# 3066H register map
File version: 1.0
Registers are 32-bit, access per field, reset 0x0 unless marked. A register's access mark holds for its fields unless they carry their own. Offsets are from the block's base; [hi:lo] are bit positions; {n}, {i} and the like mark numbered series.

## SYSCTRL1 — SYSCTRL1 peripheral interface
Base 0x10100000
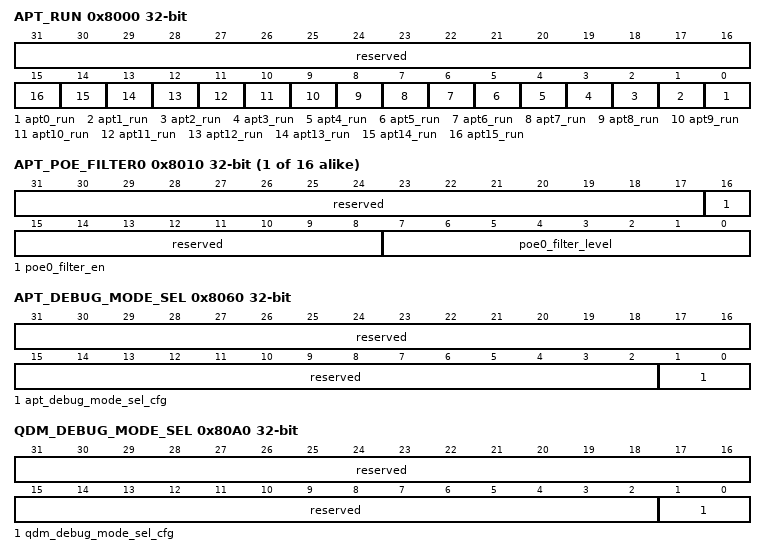
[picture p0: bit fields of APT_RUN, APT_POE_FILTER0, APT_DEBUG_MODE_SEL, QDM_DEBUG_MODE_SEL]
0x8000 APT_RUN — APT_RUN为APT使能控制寄存器。
  [31:16] reserved ro — 保留。
  [n] apt{n}_run rw (n=0..15) — APT{n}使能。 0：不使能； 1：使能。
{0x8010+4i} APT_POE_FILTER{i} (i=0..15) — APT_POE_FILTER{i}为APT POE滤波控制寄存器。
  [31:17] reserved ro — 保留。
  [16] poe{i}_filter_en rw — POE{i} FILTER使能。 0：不使能； 1：使能。
  [15:8] reserved ro — 保留域。
  [7:0] poe{i}_filter_level rw — POE{i} FILTER周期数（系统总线时钟）。
0x8060 APT_DEBUG_MODE_SEL — APT_DEBUG_MODE_SEL为APT DEBUG模式来源选择寄存器。
  [31:2] reserved ro — 保留。
  [1:0] apt_debug_mode_sel_cfg rw — APT debug源头选择。 00：CPU0的debug模式； 01：CPU1的debug模式； 10：CPU2的debug模式； 其他：CPU0的debug模式。
0x80A0 QDM_DEBUG_MODE_SEL — QDM_DEBUG_MODE_SEL为QDM0 DEBUG模式来源选择寄存器。
  [31:2] reserved ro — 保留。
  [1:0] qdm_debug_mode_sel_cfg rw — QDM debug源头选择。 00：CPU0的debug模式； 01：CPU1的debug模式； 10：CPU2的debug模式； 其他：CPU0的debug模式。
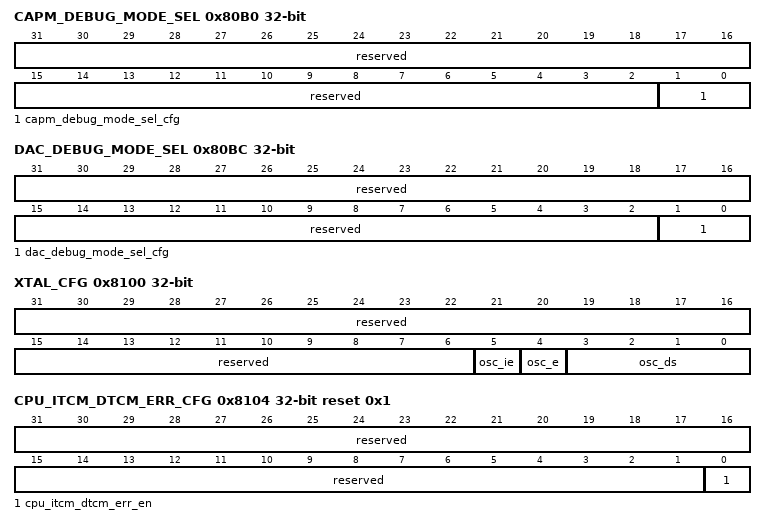
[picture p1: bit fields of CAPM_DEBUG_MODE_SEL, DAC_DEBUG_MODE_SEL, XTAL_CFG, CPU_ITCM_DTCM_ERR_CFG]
0x80B0 CAPM_DEBUG_MODE_SEL — CAPM_DEBUG_MODE_SEL为CAPM DEBUG模式来源选择。
  [31:2] reserved ro — 保留。
  [1:0] capm_debug_mode_sel_cfg rw — CAPM debug源头选择。 00：CPU0的debug模式； 01：CPU1的debug模式； 10：CPU2的debug模式； 其他：CPU0的debug模式。
0x80BC DAC_DEBUG_MODE_SEL — DAC_DEBUG_MODE_SEL为DAC DEBUG模式来源选择。
  [31:2] reserved ro — 保留。
  [1:0] dac_debug_mode_sel_cfg rw — DAC debug源头选择。 00：CPU0的debug模式； 01：CPU1的debug模式； 10：CPU2的debug模式； 其他：CPU0的debug模式。
0x8100 XTAL_CFG — XTAL_CFG为晶体IO控制寄存器。
  [31:6] reserved ro — 保留。
  [5] osc_ie rw — 晶体IO时钟输入使能。 0：不使能； 1：使能。
  [4] osc_e rw — 晶体IO谐振buf使能。 0：不使能； 1：使能。
  [3:0] osc_ds rw — 晶体IO驱动能力配置。 配置值越大，驱动能力越大。
0x8104 CPU_ITCM_DTCM_ERR_CFG reset 0x1 — CPU_ITCM_DTCM_ERR_CFG为CPU访问IDH保护区域错误配置寄存器。
  [31:1] reserved ro — 保留。
  [0] cpu_itcm_dtcm_err_en rw — CPU访问IDH保护区域时是否范围err配置。 0：不返回err； 1：返回err。
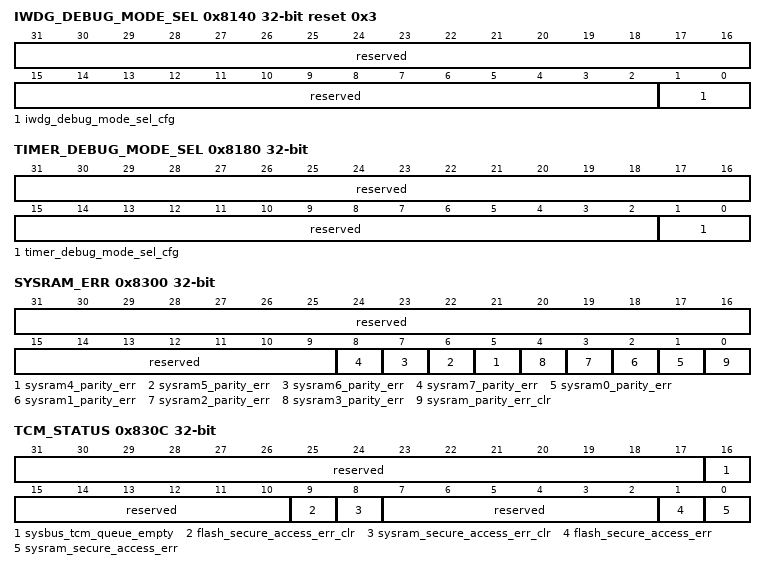
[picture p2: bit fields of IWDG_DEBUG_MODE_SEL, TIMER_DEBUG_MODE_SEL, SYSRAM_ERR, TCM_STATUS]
0x8140 IWDG_DEBUG_MODE_SEL reset 0x3 — IWDG_DEBUG_MODE_SEL为IWDG DEBUG模式来源选择寄存器。
  [31:2] reserved ro — 保留。
  [1:0] iwdg_debug_mode_sel_cfg rw — IWDG debug源头选择。 00：CPU0的debug模式； 01：CPU1的debug模式； 10：CPU2的debug模式； 其他：CPU0/1/2中任一个的debug模式。
0x8180 TIMER_DEBUG_MODE_SEL — TIMER_DEBUG_MODE_SEL为TIMER DEBUG模式来源选择寄存器。
  [31:2] reserved ro — 保留。
  [1:0] timer_debug_mode_sel_cfg rw — TIMER debug源头选择。 00：CPU0的debug模式； 01：CPU1的debug模式； 10：CPU2的debug模式； 其他：CPU0的debug模式。
0x8204 CPU1_REG_BASE rw — CPU1_REG_BASE为CPU1的软件启动地址。
  [31:0] cpu1_reg_base — CPU1的软件启动地址。
0x8208 CPU2_REG_BASE rw — CPU2_REG_BASE为CPU2的软件启动地址。
  [31:0] cpu2_reg_base — CPU2的软件启动地址。
0x8300 SYSRAM_ERR — SYSRAM_ERR为SYSRAM状态寄存器。
  [31:9] reserved ro — 保留。
  [n+1] sysram{n}_parity_err ro (n=4..7) — SYSRAM{n+1} {64n-256}K~{64n-193}K奇偶校验错误状态。 0：无错误； 1：有错误。
  [n+1] sysram{n}_parity_err ro (n=0..3) — SYSRAM{n} {64n}K~{64n+63}K奇偶校验错误状态。 0：无错误； 1：有错误。
  [0] sysram_parity_err_clr wo — SYSRAM奇偶校验错误状态清除。 向该位域写1，会清除SYSRAM奇偶校验错误状态。
0x830C TCM_STATUS — TCM_STATUS为TCM访问状态寄存器。
  [31:17] reserved ro — 保留。
  [16] sysbus_tcm_queue_empty ro — Master 通过SYS总线访问SRAM和EFLASH时，总线上的访问队列FIFO空标识。 0：访问队列非空； 1：访问队列为空。
  [15:10] reserved ro — 保留。
  [9] flash_secure_access_err_clr wo — FLASH DTCM安全访问状态。 向该位域写1，会清除FLASH DTCM安全访问错误状态。
  [8] sysram_secure_access_err_clr wo — SYSRAM DTCM安全访问状态。 向该位域写1，会清除SYSRAM DTCM安全访问错误状态。
  [7:2] reserved ro — 保留。
  [1] flash_secure_access_err ro — FLASH DTCM安全访问状态。 0：无非法访问； 1：有非法访问。
  [0] sysram_secure_access_err ro — SYSRAM DTCM安全访问状态。 0：无非法访问； 1：有非法访问。
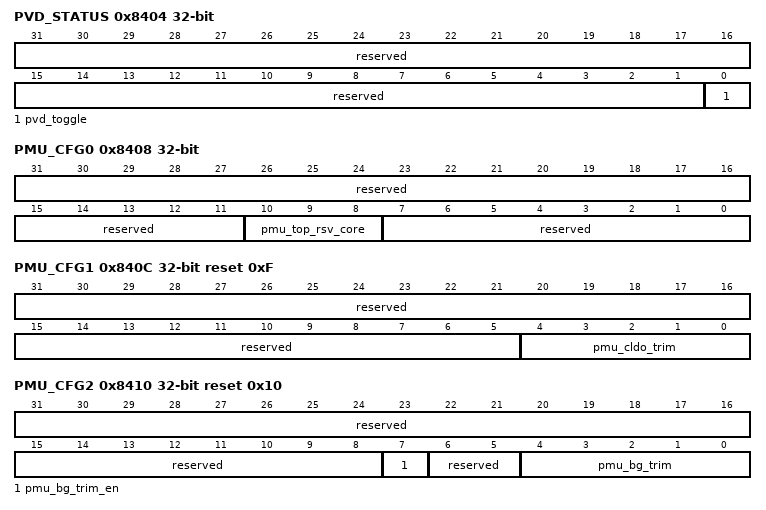
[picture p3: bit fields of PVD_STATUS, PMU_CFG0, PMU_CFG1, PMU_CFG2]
0x8404 PVD_STATUS access not given — PVD_STATUS为PVD状态寄存器。
  [31:1] reserved ro — 保留。
  [0] pvd_toggle — PVD中断。写1清零。 0：无PVD； 1：有PVD。
0x8408 PMU_CFG0 — PMU_CFG0为PMU配置寄存器0。
  [31:11] reserved ro — 保留。
  [10:8] pmu_top_rsv_core rw — PMU顶层控制保留寄存器。
  [7:0] reserved ro — 保留。
0x840C PMU_CFG1 reset 0xF — PMU_CFG1为PMU配置寄存器1。
  [31:5] reserved ro — 保留。
  [4:0] pmu_cldo_trim rw — PMU CLDO trim值。 值越大，输出电压越高。
0x8410 PMU_CFG2 reset 0x10 — PMU_CFG2为PMU配置寄存器2。
  [31:8] reserved ro — 保留。
  [7] pmu_bg_trim_en rw — PMU BG trim值源选择。 0：来源于EFC控制器上电时从NVR_CFG自动加载； 1：来源于系统控制器配置。
  [6:5] reserved ro — 保留。
  [4:0] pmu_bg_trim rw — PMU BG trim值。 值越大，输出电压越低。
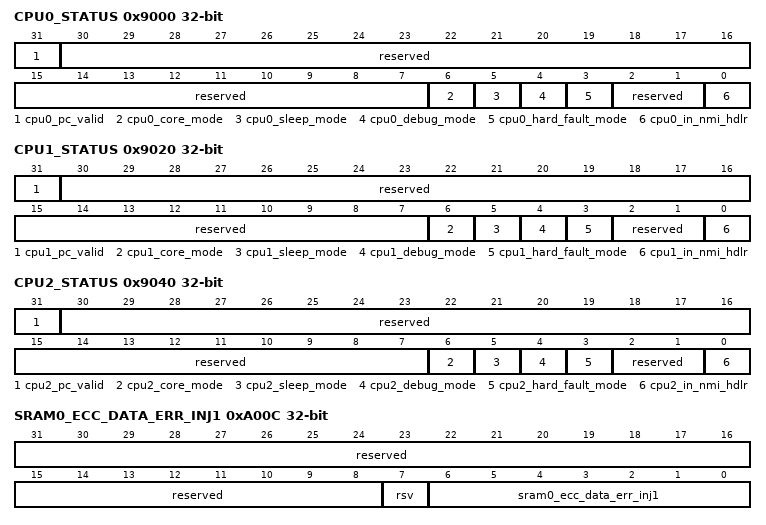
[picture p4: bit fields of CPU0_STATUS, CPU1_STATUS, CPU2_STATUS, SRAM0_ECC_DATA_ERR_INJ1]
0x9000 CPU0_STATUS ro — CPU0_STATUS为CPU0状态寄存器。
  [31] cpu0_pc_valid — CPU0 PC值有效状态。 0：PC值无效； 1：PC值有效。
  [30:7] reserved — 保留。
  [6] cpu0_core_mode — CPU0当前状态指示。 0：user mode； 1：machine mode。
  [5] cpu0_sleep_mode — CPU SLEEP状态。 0：非sleep状态； 1：sleep状态。
  [4] cpu0_debug_mode — CPU DEBUG状态。 0：非debug状态； 1：debug状态。
  [3] cpu0_hard_fault_mode — CPU HARD FAULT状态。 0：非hard_fault状态； 1：hard_fault状态。
  [2:1] reserved — 保留。
  [0] cpu0_in_nmi_hdlr — CPU NMI处理状态。 0：非NMI处理状态； 1：NMI处理状态。
{0x9004+0x20*i} CPU{i}_PC ro (i=0..2) — CPU{i}_PC为CPU{i}的实时PC值。
  [31:0] cpu{i}_pc — CPU{i} PC值。
0x9020 CPU1_STATUS ro — CPU1_STATUS为CPU1状态寄存器。
  [31] cpu1_pc_valid — CPU0 PC值有效状态。 0：PC值无效； 1：PC值有效。
  [30:7] reserved — 保留。
  [6] cpu1_core_mode — CPU1 当前状态指示。 0：user mode； 1：machine mode。
  [5] cpu1_sleep_mode — CPU SLEEP状态。 0：非sleep状态； 1：sleep状态。
  [4] cpu1_debug_mode — CPU DEBUG状态。 0：非debug状态； 1：debug状态。
  [3] cpu1_hard_fault_mode — CPU HARD FAULT状态。 0：非hard_fault状态； 1：hard_fault状态。
  [2:1] reserved — 保留。
  [0] cpu1_in_nmi_hdlr — CPU NMI处理状态。 0：非NMI处理状态； 1：NMI处理状态。
0x9040 CPU2_STATUS ro — CPU2_STATUS为CPU2状态寄存器。
  [31] cpu2_pc_valid — CPU0 PC值有效状态。 0：PC值无效； 1：PC值有效。
  [30:7] reserved — 保留。
  [6] cpu2_core_mode — CPU2 当前状态指示。 0：user mode； 1：machine mode。
  [5] cpu2_sleep_mode — CPU SLEEP状态。 0：非sleep状态； 1：sleep状态。
  [4] cpu2_debug_mode — CPU DEBUG状态。 0：非debug状态； 1：debug状态。
  [3] cpu2_hard_fault_mode — CPU HARD FAULT状态。 0：非hard_fault状态； 1：hard_fault状态。
  [2:1] reserved — 保留。
  [0] cpu2_in_nmi_hdlr — CPU NMI处理状态。 0：非NMI处理状态； 1：NMI处理状态。
0xA000 SRAM0_ECC_ERR_ADDR ro — SRAM0_ECC_ERR_ADDR为ECC_SRAM0的ECC首错误地址寄存器。
  [31:0] sram0_ecc_err_addr — SRAM0发生ECC错误的地址。
0xA004 SRAM7_ECC_ERR_ADDR ro — SRAM7_ECC_ERR_ADDR为ECC_SRAM1的ECC首错误地址寄存器。
  [31:0] sram7_ecc_err_addr — SRAM7发生ECC错误的地址。
0xA008 SRAM0_ECC_DATA_ERR_INJ0 rw — SRAM0_ECC_DATA_ERR_INJ0为ECC_SRAM0的ECC错误注入的低32位数据寄存器。
  [31:0] sram0_ecc_data_err_inj0 — SRAM0 ECC注错低32位数据。
0xA00C SRAM0_ECC_DATA_ERR_INJ1 — SRAM0_ECC_DATA_ERR_INJ1为ECC_SRAM0的ECC错误注入的高7位数据寄存器。
  [31:8] reserved ro — 保留。
  [7] rsv rw — 保留。
  [6:0] sram0_ecc_data_err_inj1 rw — SRAM0 ECC注错高7位数据。
0xA010 SRAM7_ECC_ERR_INJ0 rw — SRAM7_ECC_ERR_INJ0为ECC_SRAM1的ECC错误注入的低32位数据寄存器。
  [31:0] sram7_ecc_data_err_inj0 — SRAM7 ECC注错低32位数据。
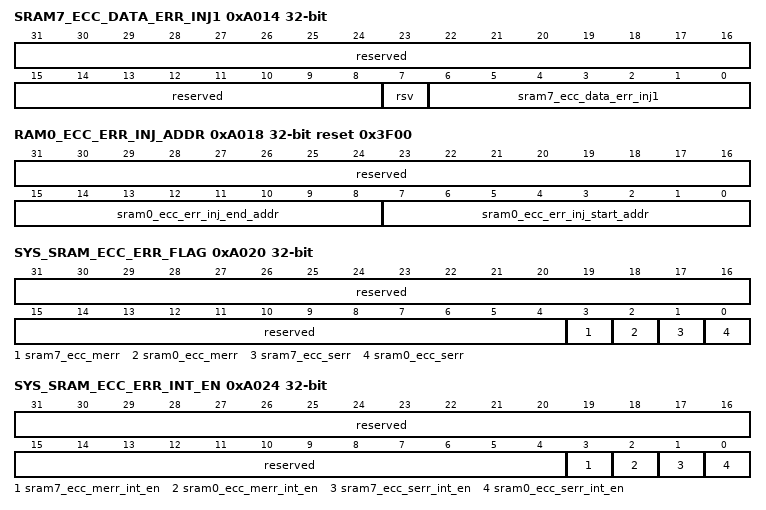
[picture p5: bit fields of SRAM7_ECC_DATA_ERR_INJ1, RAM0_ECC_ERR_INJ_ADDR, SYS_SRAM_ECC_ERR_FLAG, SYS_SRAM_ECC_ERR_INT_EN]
0xA014 SRAM7_ECC_DATA_ERR_INJ1 — SRAM7_ECC_DATA_ERR_INJ1为ECC_SRAM1的ECC错误注入的高7位数据寄存器。
  [31:8] reserved ro — 保留。
  [7] rsv rw — 保留。
  [6:0] sram7_ecc_data_err_inj1 rw — SRAM7 ECC注错高7位数据。
0xA018 RAM0_ECC_ERR_INJ_ADDR reset 0x3F00 — RAM0_ECC_ERR_INJ_ADDR为ECC_SRAM0的ECC错误注入地址配置寄存器。
  [31:16] reserved ro — 保留。
  [15:8] sram0_ecc_err_inj_end_addr rw — SRAM0，64K ECC错误地址注入的结束地址。
  [7:0] sram0_ecc_err_inj_start_addr rw — SRAM0，64K ECC错误地址注入的起始地址。
0xA020 SYS_SRAM_ECC_ERR_FLAG access not given — SYS_SRAM_ECC_ERR_FLAG为系统SRAM ECC错误原始中断寄存器。
  [31:4] reserved ro — 保留。
  [3] sram7_ecc_merr — sram7_ecc_merr的原始中断。 写1清零。
  [2] sram0_ecc_merr — sram0_ecc_merr的原始中断。 写1清零。
  [1] sram7_ecc_serr — sram7_ecc_serr的原始中断。 写1清零。
  [0] sram0_ecc_serr — sram0_ecc_serr的原始中断。 写1清零。
0xA024 SYS_SRAM_ECC_ERR_INT_EN — SYS_SRAM_ECC_ERR_INT_EN为系统SRAM ECC错误中断使能寄存器。
  [31:4] reserved ro — 保留。
  [3] sram7_ecc_merr_int_en rw — sram7_ecc_merr中断上报使能。 0：不使能中断上报； 1：使能中断上报。
  [2] sram0_ecc_merr_int_en rw — sram0_ecc_merr中断上报使能。 0：不使能中断上报； 1：使能中断上报。
  [1] sram7_ecc_serr_int_en rw — sram7_ecc_serr中断上报使能。 0：不使能中断上报； 1：使能中断上报。
  [0] sram0_ecc_serr_int_en rw — sram0_ecc_serr中断上报使能。 0：不使能中断上报； 1：使能中断上报。
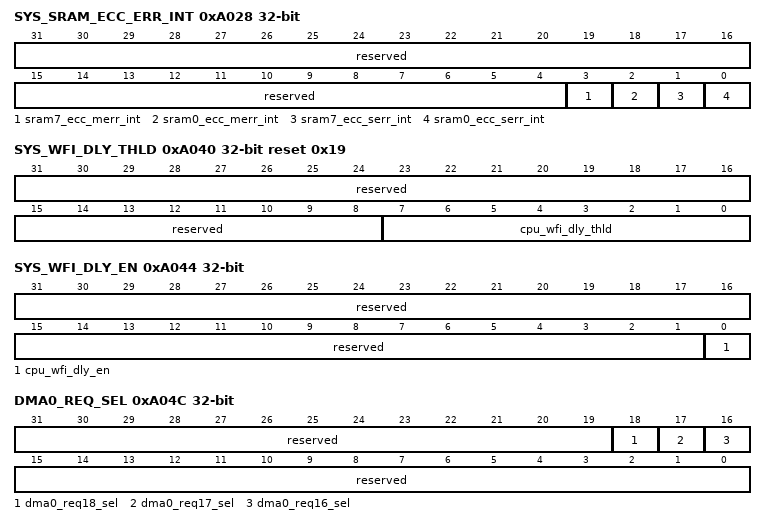
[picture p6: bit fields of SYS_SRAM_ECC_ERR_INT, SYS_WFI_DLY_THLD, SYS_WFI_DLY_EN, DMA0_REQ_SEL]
0xA028 SYS_SRAM_ECC_ERR_INT ro — SYS_SRAM_ECC_ERR_INT为系统SRAM ECC错误屏蔽后的中断状态寄存器。
  [31:4] reserved — 保留。
  [3] sram7_ecc_merr_int — sram7_ecc_merr屏蔽后中断状态。 0：屏蔽后无中断； 1：屏蔽后有中断。
  [2] sram0_ecc_merr_int — sram0_ecc_merr屏蔽后中断状态。 0：屏蔽后无中断； 1：屏蔽后有中断。
  [1] sram7_ecc_serr_int — sram7_ecc_serr屏蔽后中断状态。 0：屏蔽后无中断； 1：屏蔽后有中断。
  [0] sram0_ecc_serr_int — sram0_ecc_serr中屏蔽后中断状态。 0：屏蔽后无中断； 1：屏蔽后有中断。
0xA040 SYS_WFI_DLY_THLD reset 0x19 — SYS_WFI_DLY_THLD为系统WFI错峰唤醒阈值配置寄存器。
  [31:8] reserved ro — 保留。
  [7:0] cpu_wfi_dly_thld rw — 3个CPU同时从WFI唤醒时，错峰计数阈值，默认25个cycle。
0xA044 SYS_WFI_DLY_EN — SYS_WFI_DLY_EN为系统WFI错峰唤醒使能配置寄存器。
  [31:1] reserved ro — 保留。
  [0] cpu_wfi_dly_en rw — CPU WFI唤醒错峰使能。 0：不使能错峰功能； 1：使能错峰功能。
0xA04C DMA0_REQ_SEL — DMA0_REQ_SEL为DMA0请求线源选择寄存器。
  [31:19] reserved ro — 保留。
  [18] dma0_req18_sel rw — DMA0请求线18源选择。 0：CAPM2； 1：ADC1_2。
  [17] dma0_req17_sel rw — DMA0请求线17源选择。 0：CAPM1； 1：ADC0_2。
  [16] dma0_req16_sel rw — DMA0请求线16源选择。 0：CAPM0； 1：ADC1_1。
  [15:0] reserved ro — 保留。
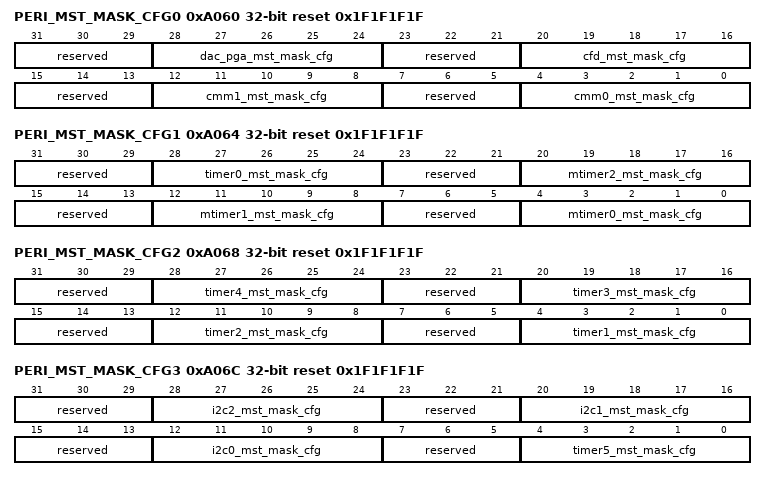
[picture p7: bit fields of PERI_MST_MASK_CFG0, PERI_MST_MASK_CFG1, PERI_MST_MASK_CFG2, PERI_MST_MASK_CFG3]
0xA060 PERI_MST_MASK_CFG0 access not given reset 0x1F1F1F1F — PERI_MST_MASK_CFG0为外设MASETER访问权限配置0。
  [31:29] reserved ro — 保留。
  [28:24] dac_pga_mst_mask_cfg — DAC_PGA_ACMP的MASTER访问权限控制。 bit[4]：DMA1。 bit[3]：DMA0。 bit[2]：CPU2。 bit[1]：CPU1。 bit[0]：CPU0。
  [23:21] reserved ro — 保留。
  [20:16] cfd_mst_mask_cfg — CFD的MASTER访问权限控制。 bit[4]：DMA1。 bit[3]：DMA0。 bit[2]：CPU2。 bit[1]：CPU1。 bit[0]：CPU0。
  [15:13] reserved ro — 保留。
  [12:8] cmm1_mst_mask_cfg — CMM1的MASTER访问权限控制。 bit[4]：DMA1。 bit[3]：DMA0。 bit[2]：CPU2。 bit[1]：CPU1。 bit[0]：CPU0。
  [7:5] reserved ro — 保留。
  [4:0] cmm0_mst_mask_cfg — CMM0的MASTER访问权限控制。 bit[4]：DMA1。 bit[3]：DMA0。 bit[2]：CPU2。 bit[1]：CPU1。 bit[0]：CPU0。
0xA064 PERI_MST_MASK_CFG1 access not given reset 0x1F1F1F1F — PERI_MST_MASK_CFG1为外设MASETER访问权限配置1。
  [31:29] reserved ro — 保留。
  [28:24] timer0_mst_mask_cfg — TIMER0的MASTER访问权限控制。 bit[4]：DMA1。 bit[3]：DMA0。 bit[2]：CPU2。 bit[1]：CPU1。 bit[0]：CPU0。
  [23:21] reserved ro — 保留。
  [20:16] mtimer2_mst_mask_cfg — MTIMER2的MASTER访问权限控制。 bit[4]：DMA1。 bit[3]：DMA0。 bit[2]：CPU2。 bit[1]：CPU1。 bit[0]：CPU0。
  [15:13] reserved ro — 保留。
  [12:8] mtimer1_mst_mask_cfg — MTIMER1的MASTER访问权限控制。 bit[4]：DMA1。 bit[3]：DMA0。 bit[2]：CPU2。 bit[1]：CPU1。 bit[0]：CPU0。
  [7:5] reserved ro — 保留。
  [4:0] mtimer0_mst_mask_cfg — MTIMER0的MASTER访问权限控制。 bit[4]：DMA1。 bit[3]：DMA0。 bit[2]：CPU2。 bit[1]：CPU1。 bit[0]：CPU0。
0xA068 PERI_MST_MASK_CFG2 access not given reset 0x1F1F1F1F — PERI_MST_MASK_CFG2为外设MASETER访问权限配置2。
  [31:29] reserved ro — 保留。
  [8n-4:8n-8] timer{n}_mst_mask_cfg (n=1..4) — TIMER{n}的MASTER访问权限控制。 bit[4]：DMA1。 bit[3]：DMA0。 bit[2]：CPU2。 bit[1]：CPU1。 bit[0]：CPU0。
  [23:21] reserved ro — 保留。
  [15:13] reserved ro — 保留。
  [7:5] reserved ro — 保留。
0xA06C PERI_MST_MASK_CFG3 access not given reset 0x1F1F1F1F — PERI_MST_MASK_CFG3为外设MASETER访问权限配置3。
  [31:29] reserved ro — 保留。
  [28:24] i2c2_mst_mask_cfg — I2C2的MASTER访问权限控制。 bit[4]：DMA1。 bit[3]：DMA0。 bit[2]：CPU2。 bit[1]：CPU1。 bit[0]：CPU0。
  [23:21] reserved ro — 保留。
  [20:16] i2c1_mst_mask_cfg — I2C1的MASTER访问权限控制。 bit[4]：DMA1。 bit[3]：DMA0。 bit[2]：CPU2。 bit[1]：CPU1。 bit[0]：CPU0。
  [15:13] reserved ro — 保留。
  [12:8] i2c0_mst_mask_cfg — I2C0的MASTER访问权限控制。 bit[4]：DMA1。 bit[3]：DMA0。 bit[2]：CPU2。 bit[1]：CPU1。 bit[0]：CPU0。
  [7:5] reserved ro — 保留。
  [4:0] timer5_mst_mask_cfg — TIMER5的MASTER访问权限控制。 bit[4]：DMA1。 bit[3]：DMA0。 bit[2]：CPU2。 bit[1]：CPU1。 bit[0]：CPU0。
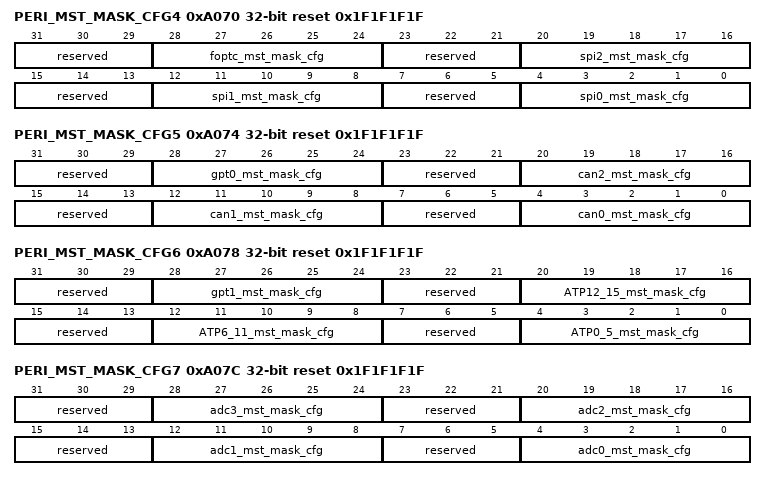
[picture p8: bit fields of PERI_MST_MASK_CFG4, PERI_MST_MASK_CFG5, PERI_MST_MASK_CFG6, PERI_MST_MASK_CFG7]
0xA070 PERI_MST_MASK_CFG4 access not given reset 0x1F1F1F1F — PERI_MST_MASK_CFG4为外设MASETER访问权限配置4。
  [31:29] reserved ro — 保留。
  [28:24] foptc_mst_mask_cfg — FOTPC的MASTER访问权限控制。 bit[4]：DMA1。 bit[3]：DMA0。 bit[2]：CPU2。 bit[1]：CPU1。 bit[0]：CPU0。
  [23:21] reserved ro — 保留。
  [20:16] spi2_mst_mask_cfg — SPI2的MASTER访问权限控制。 bit[4]：DMA1。 bit[3]：DMA0。 bit[2]：CPU2。 bit[1]：CPU1。 bit[0]：CPU0。
  [15:13] reserved ro — 保留。
  [12:8] spi1_mst_mask_cfg — SPI1的MASTER访问权限控制。 bit[4]：DMA1。 bit[3]：DMA0。 bit[2]：CPU2。 bit[1]：CPU1。 bit[0]：CPU0。
  [7:5] reserved ro — 保留。
  [4:0] spi0_mst_mask_cfg — SPI0的MASTER访问权限控制。 bit[4]：DMA1。 bit[3]：DMA0。 bit[2]：CPU2。 bit[1]：CPU1。 bit[0]：CPU0。
0xA074 PERI_MST_MASK_CFG5 access not given reset 0x1F1F1F1F — PERI_MST_MASK_CFG5为外设MASETER访问权限配置5。
  [31:29] reserved ro — 保留。
  [28:24] gpt0_mst_mask_cfg — GPT0的MASTER访问权限控制。 bit[4]：DMA1。 bit[3]：DMA0。 bit[2]：CPU2。 bit[1]：CPU1。 bit[0]：CPU0。
  [23:21] reserved ro — 保留。
  [20:16] can2_mst_mask_cfg — CAN2的MASTER访问权限控制。 bit[4]：DMA1。 bit[3]：DMA0。 bit[2]：CPU2。 bit[1]：CPU1。 bit[0]：CPU0。
  [15:13] reserved ro — 保留。
  [12:8] can1_mst_mask_cfg — CAN1的MASTER访问权限控制。 bit[4]：DMA1。 bit[3]：DMA0。 bit[2]：CPU2。 bit[1]：CPU1。 bit[0]：CPU0。
  [7:5] reserved ro — 保留。
  [4:0] can0_mst_mask_cfg — CAN0的MASTER访问权限控制。 bit[4]：DMA1。 bit[3]：DMA0。 bit[2]：CPU2。 bit[1]：CPU1。 bit[0]：CPU0。
0xA078 PERI_MST_MASK_CFG6 access not given reset 0x1F1F1F1F — PERI_MST_MASK_CFG6为外设MASETER访问权限配置6。
  [31:29] reserved ro — 保留。
  [28:24] gpt1_mst_mask_cfg — I2C0的MASTER访问权限控制。 bit[4]：DMA1。 bit[3]：DMA0。 bit[2]：CPU2。 bit[1]：CPU1。 bit[0]：CPU0。
  [23:21] reserved ro — 保留。
  [20:16] ATP12_15_mst_mask_cfg — SPI2的MASTER访问权限控制。 bit[4]：DMA1。 bit[3]：DMA0。 bit[2]：CPU2。 bit[1]：CPU1。 bit[0]：CPU0。
  [15:13] reserved ro — 保留。
  [12:8] ATP6_11_mst_mask_cfg — SPI1的MASTER访问权限控制。 bit[4]：DMA1。 bit[3]：DMA0。 bit[2]：CPU2。 bit[1]：CPU1。 bit[0]：CPU0。
  [7:5] reserved ro — 保留。
  [4:0] ATP0_5_mst_mask_cfg — SPI0的MASTER访问权限控制。 bit[4]：DMA1。 bit[3]：DMA0。 bit[2]：CPU2。 bit[1]：CPU1。 bit[0]：CPU0。
0xA07C PERI_MST_MASK_CFG7 access not given reset 0x1F1F1F1F — PERI_MST_MASK_CFG7为外设MASETER访问权限配置7。
  [31:29] reserved ro — 保留。
  [28:24] adc3_mst_mask_cfg — I2C0的MASTER访问权限控制。 bit[4]：DMA1。 bit[3]：DMA0。 bit[2]：CPU2。 bit[1]：CPU1。 bit[0]：CPU0。
  [23:21] reserved ro — 保留。
  [20:16] adc2_mst_mask_cfg — SPI2的MASTER访问权限控制。 bit[4]：DMA1。 bit[3]：DMA0。 bit[2]：CPU2。 bit[1]：CPU1。 bit[0]：CPU0。
  [15:13] reserved ro — 保留。
  [12:8] adc1_mst_mask_cfg — SPI1的MASTER访问权限控制。 bit[4]：DMA1。 bit[3]：DMA0。 bit[2]：CPU2。 bit[1]：CPU1。 bit[0]：CPU0。
  [7:5] reserved ro — 保留。
  [4:0] adc0_mst_mask_cfg — SPI0的MASTER访问权限控制。 bit[4]：DMA1。 bit[3]：DMA0。 bit[2]：CPU2。 bit[1]：CPU1。 bit[0]：CPU0。
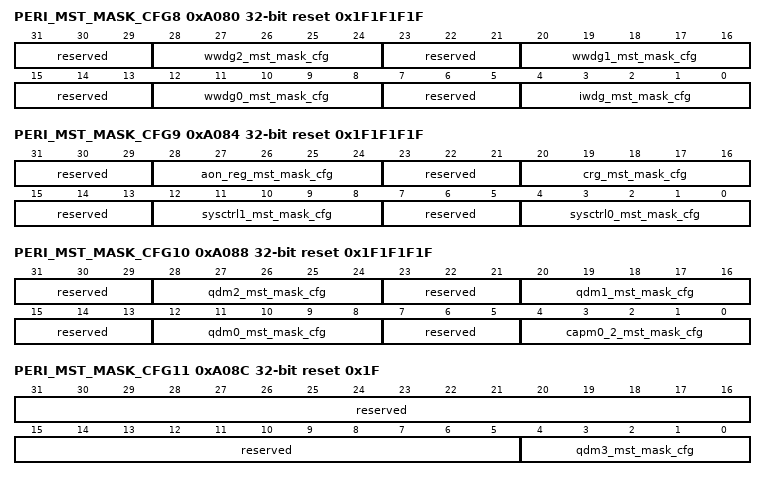
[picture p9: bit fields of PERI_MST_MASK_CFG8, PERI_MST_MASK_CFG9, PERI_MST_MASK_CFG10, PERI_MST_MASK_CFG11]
0xA080 PERI_MST_MASK_CFG8 access not given reset 0x1F1F1F1F — PERI_MST_MASK_CFG8为外设MASETER访问权限配置8。
  [31:29] reserved ro — 保留。
  [28:24] wwdg2_mst_mask_cfg — I2C0的MASTER访问权限控制。 bit[4]：DMA1。 bit[3]：DMA0。 bit[2]：CPU2。 bit[1]：CPU1。 bit[0]：CPU0。
  [23:21] reserved ro — 保留。
  [20:16] wwdg1_mst_mask_cfg — SPI2的MASTER访问权限控制。 bit[4]：DMA1。 bit[3]：DMA0。 bit[2]：CPU2。 bit[1]：CPU1。 bit[0]：CPU0。
  [15:13] reserved ro — 保留。
  [12:8] wwdg0_mst_mask_cfg — SPI1的MASTER访问权限控制。 bit[4]：DMA1。 bit[3]：DMA0。 bit[2]：CPU2。 bit[1]：CPU1。 bit[0]：CPU0。
  [7:5] reserved ro — 保留。
  [4:0] iwdg_mst_mask_cfg — SPI0的MASTER访问权限控制。 bit[4]：DMA1。 bit[3]：DMA0。 bit[2]：CPU2。 bit[1]：CPU1。 bit[0]：CPU0。
0xA084 PERI_MST_MASK_CFG9 access not given reset 0x1F1F1F1F — PERI_MST_MASK_CFG9为外设MASETER访问权限配置9。
  [31:29] reserved ro — 保留。
  [28:24] aon_reg_mst_mask_cfg — I2C0的MASTER访问权限控制。 bit[4]：DMA1。 bit[3]：DMA0。 bit[2]：CPU2。 bit[1]：CPU1。 bit[0]：CPU0。
  [23:21] reserved ro — 保留。
  [20:16] crg_mst_mask_cfg — SPI2的MASTER访问权限控制。 bit[4]：DMA1。 bit[3]：DMA0。 bit[2]：CPU2。 bit[1]：CPU1。 bit[0]：CPU0。
  [15:13] reserved ro — 保留。
  [12:8] sysctrl1_mst_mask_cfg — SPI1的MASTER访问权限控制。 bit[4]：DMA1。 bit[3]：DMA0。 bit[2]：CPU2。 bit[1]：CPU1。 bit[0]：CPU0。
  [7:5] reserved ro — 保留。
  [4:0] sysctrl0_mst_mask_cfg — SPI0的MASTER访问权限控制。 bit[4]：DMA1。 bit[3]：DMA0。 bit[2]：CPU2。 bit[1]：CPU1。 bit[0]：CPU0。
0xA088 PERI_MST_MASK_CFG10 access not given reset 0x1F1F1F1F — PERI_MST_MASK_CFG10为外设MASETER访问权限配置10。
  [31:29] reserved ro — 保留。
  [28:24] qdm2_mst_mask_cfg — I2C0的MASTER访问权限控制。 bit[4]：DMA1。 bit[3]：DMA0。 bit[2]：CPU2。 bit[1]：CPU1。 bit[0]：CPU0。
  [23:21] reserved ro — 保留。
  [20:16] qdm1_mst_mask_cfg — SPI2的MASTER访问权限控制。 bit[4]：DMA1。 bit[3]：DMA0。 bit[2]：CPU2。 bit[1]：CPU1。 bit[0]：CPU0。
  [15:13] reserved ro — 保留。
  [12:8] qdm0_mst_mask_cfg — SPI1的MASTER访问权限控制。 bit[4]：DMA1。 bit[3]：DMA0。 bit[2]：CPU2。 bit[1]：CPU1。 bit[0]：CPU0。
  [7:5] reserved ro — 保留。
  [4:0] capm0_2_mst_mask_cfg — SPI0的MASTER访问权限控制。 bit[4]：DMA1。 bit[3]：DMA0。 bit[2]：CPU2。 bit[1]：CPU1。 bit[0]：CPU0。
0xA08C PERI_MST_MASK_CFG11 access not given reset 0x1F — PERI_MST_MASK_CFG11为外设MASETER访问权限配置11。
  [31:5] reserved ro — 保留。
  [4:0] qdm3_mst_mask_cfg — SPI0的MASTER访问权限控制。 bit[4]：DMA1。 bit[3]：DMA0。 bit[2]：CPU2。 bit[1]：CPU1。 bit[0]：CPU0。
0xA090 PERI_MST_ACCESS_EXCEPTION_ADDR ro — PERI_MST_ACCESS_EXCEPTION_ADDR为外设MASETER访问异常的地址寄存器。
  [31:0] peri_mst_access_exception_addr — 外设访问权限发生异常时的地址。
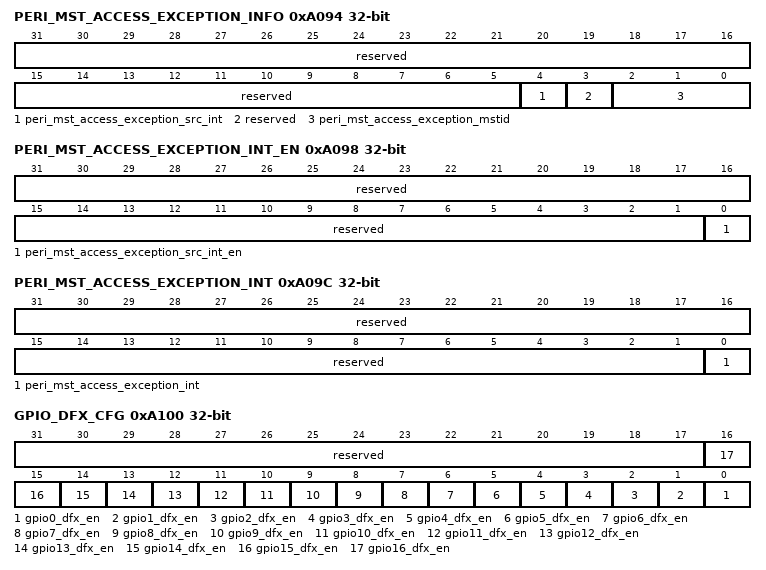
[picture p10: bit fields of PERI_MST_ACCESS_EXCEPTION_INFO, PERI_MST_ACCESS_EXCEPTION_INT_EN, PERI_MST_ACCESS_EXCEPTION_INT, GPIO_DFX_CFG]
0xA094 PERI_MST_ACCESS_EXCEPTION_INFO access not given — PERI_MST_ACCESS_EXCEPTION_INFO为外设MASETER访问异常的MST_Id和中断信息寄存器。
  [31:5] reserved ro — 保留。
  [4] peri_mst_access_exception_src_int — 外设访问权限发生异常时的原始中断。
  [3] reserved ro — 保留。
  [2:0] peri_mst_access_exception_mstid ro — 外设访问权限发生异常时的MST_Id。
0xA098 PERI_MST_ACCESS_EXCEPTION_INT_EN — PERI_MST_ACCESS_EXCEPTION_INT_EN为外设MASETER访问异常的MST_Id和中断信息寄存器。
  [31:1] reserved ro — 保留。
  [0] peri_mst_access_exception_src_int_en rw — 外设访问权限发生异常时的中断上报使能。
0xA09C PERI_MST_ACCESS_EXCEPTION_INT ro — PERI_MST_ACCESS_EXCEPTION_INT为外设MASETER访问异常的上报中断寄存器。
  [31:1] reserved — 保留。
  [0] peri_mst_access_exception_int — 外设访问权限发生异常时屏蔽后的中断。
0xA100 GPIO_DFX_CFG — GPIO_DFX_CFG为GPIO调试DFX使能配置寄存器。
  [31:17] reserved ro — 保留。
  [n] gpio{n}_dfx_en rw (n=0..16) — GPIO{n}的DFX使能。
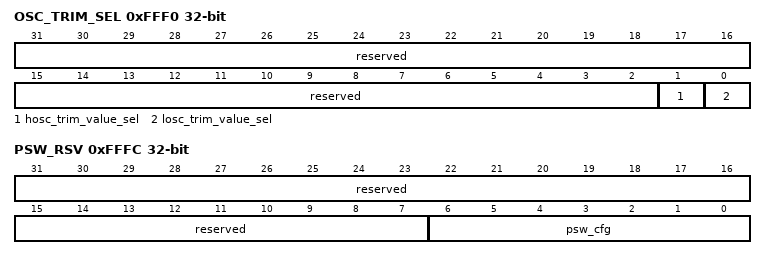
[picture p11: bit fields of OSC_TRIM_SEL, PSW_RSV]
0xFFF0 OSC_TRIM_SEL — OSC_TRIM_SEL为OSC TRIM选择配置寄存器。
  [31:2] reserved ro — 保留。
  [1] hosc_trim_value_sel rw — hosc的trim值来源选择。 0：寄存器配置； 1：sar_rtim。
  [0] losc_trim_value_sel rw — losc的trim值来源选择。 0：寄存器配置； 1：sar_rtim。
0xFFFC PSW_RSV — PSW_RSV为PWD配置寄存器。
  [31:7] reserved ro — 保留。
  [6:0] psw_cfg rw — PSW的配置。
